# STM32MP13xx register map
File version: 1.5
CPU: CA7 r0p0, little endian, MPU, FPU, 4 interrupt priority bits
Registers are 32-bit, read-write, reset 0x0 unless marked. A register's access mark holds for its fields unless they carry their own. Offsets are from the block's base; [hi:lo] are bit positions; {n}, {i} and the like mark numbered series.

## DDRPHYC (part 1 of 2)
Base 0x5A004000
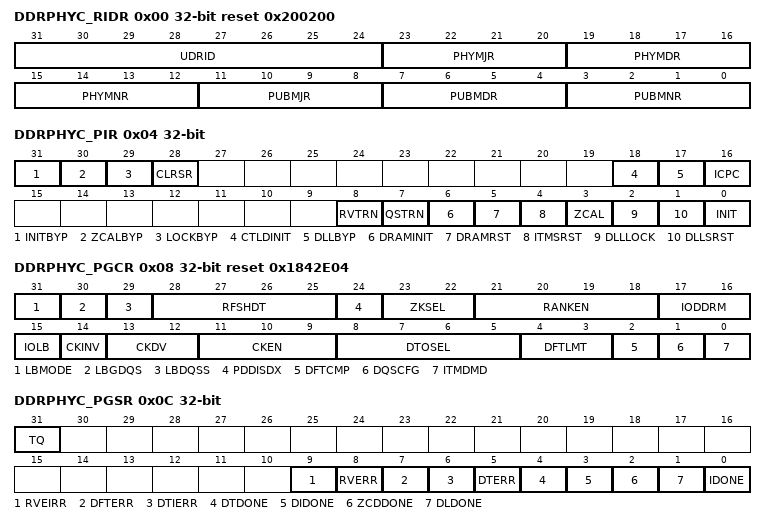
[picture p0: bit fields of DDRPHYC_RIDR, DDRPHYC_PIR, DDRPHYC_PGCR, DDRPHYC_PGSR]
0x00 DDRPHYC_RIDR ro reset 0x200200 — DDRPHYC revision ID register
  [31:24] UDRID — User-defined rev ID
  [23:20] PHYMJR — PHY maj rev
  [19:16] PHYMDR — PHY moderate rev
  [15:12] PHYMNR — PHY minor rev
  [11:8] PUBMJR — PUB maj rev
  [7:4] PUBMDR — PUB moderate rev
  [3:0] PUBMNR — PUB minor rev
0x04 DDRPHYC_PIR wo — DDRPHYC PHY initialization register
  [31] INITBYP — Initialization bypass Bypasses or stops, if set, all initialization routines currently running, including PHY initialization, DRAM initialization, and PHY training. Initialization may be triggered manually using INIT and the other relevant bits of the DDRPHYC_PIR register. This bit is self-clearing.
  [30] ZCALBYP — zcal bypass Bypasses or stops, if set, impedance calibration of all ZQ control blocks that automatically triggers after reset. Impedance calibration may be triggered manually using INIT and ZCAL bits of the DDRPHYC_PIR register. This bit is self-clearing.
  [29] LOCKBYP — DLL lock bypass Bypasses or stops, if set, the waiting of DLLs to lock. DLL lock wait is automatically triggers after reset. DLL lock wait may be triggered manually using INIT and DLLLOCK bits of the DDRPHYC_PIR register. This bit is self-clearing.
  [28] CLRSR — clear status register Writing 1 to this bits does the following: Auto-clears itself. This means a following read to bit CLRSR returns 0 Clears the DXnGSR0 bits for DTDONE, DTERR, DTIERR Clears bit DFTERR in DDRPHYC_PGSR register and bit DFTERR in DDRPHYC_DXnGSR1 register This bit is primarily for debug purposes and is typically not needed during normal functional operation. It can be used when bit IDONE=1 in PGSR register, to manually clear the PGSR status bits, however, the PGSR status bits (except for the DFTRR and TQ bits) are automatically cleared by starting a new init process. The bit can also be used to manually clear the DXnGSR status bits, however, starting a new data training process automatically clears the DXnGSR status bits.
  [18] CTLDINIT — Controller DRAM initialization Indicates if set that DRAM initialization is performed by the controller. Otherwise if not set it indicates that DRAM initialization is performed using the built-in initialization sequence or using software through the configuration port.
  [17] DLLBYP — DLL bypass A setting of 1 on this bit puts all PHY DLLs in bypass mode. A bypassed DLL is also powered down (disabled).
  [16] ICPC — Initialization complete pin configuration Specifies how the DFI 2.1 initialization complete output pin should be used to indicate the status of initialization.
    0=Asserted after PHY initialization (DLL locking and impedance calibration) is complete; 1=Asserted after PHY initialization is complete and the triggered PUBL initialization (DRAM initialization, data training, or initialization trigger with no selected initialization) is complete
  [8] RVTRN — Read DQS gate training DQSTRN) and RV training (RVTRN) should normally be run together. It is expected RVTRN is normally set whenever bit QSTRN is set. If RVTRN=1 and bit QSTRN=0, when bit INIT=1 (triggering the init process) the read DQS gate training algorithm still runs (as if bit QSTRN in DDRPHYC_PIR register was actually set to 1). If it is necessary to run only RV training stand-alone, with no read DQS gate training, you can prevent the read DQS gate training from running by setting bit LBGDQS=1 in DDRPHYC_PGCR register. Note: RV training cannot use multi-purpose register (MPR) and must use the user data programmed in DTDR0-1. Note: RVTRN is not applicable to this version of PUBL.
  [7] QSTRN — Read DQS training Executes a PUBL training routine to determine the optimum position of the read data DQS strobe for maximum system timing margins.
  [6] DRAMINIT — DRAM initialization Executes the DRAM initialization sequence
  [5] DRAMRST — DRAM reset (DDR3 only) Issues a reset to the DRAM (by driving the DRAM reset pin low) and wait 200us. This can be triggered in isolation or with the full DRAM initialization (DRAMINIT). For the latter case, the reset is issued and 200us is waited before starting the full initialization sequence.
  [4] ITMSRST — ITM reset Soft resets the interface timing modules for the data and data strobes, i.e., it asserts the ITM soft reset (srstb) signal.
  [3] ZCAL — Impedance calibration (Driver and ODT) Performs PHY impedance calibration.
  [2] DLLLOCK — DLL lock Waits for the PHY DLLs to lock.
  [1] DLLSRST — DLL soft reset Soft resets all PHY DLLs by driving the DLL soft reset pin. Note: - Requires that ctl_clk be toggling for the DLL soft reset signal to be output from the DLL. If ctl_clk (AC DLL's cclk_0) is not guaranteed to be toggling, it is recommended to use the manual DLL soft reset bit DLLSRST of DDRPHYC_ACDLLCR, and not bit DLLSRST of DDRPHYC_PIR. - Ensure that the minimum requirements for DLL bypass and DLL reset are observed while asserting this bit.
  [0] INIT — Initialization trigger A write of '1' to this bit triggers the DDR system initialization, including PHY initialization, DRAM initialization, and PHY training. The exact initialization steps to be executes are specified in bits 1 to 6 of this register. A bit setting of 1 means the step is executed as part of the initialization sequence, while a setting of '0â means the step is bypassed. The initialization trigger bit is self-clearing.
0x08 DDRPHYC_PGCR reset 0x1842E04 — DDRPHYC PHY global control register
  [31] LBMODE — Loop back mode Indicates if set that the PHY/PUB is in loopback mode
  [30] LBGDQS — Loop back DQS gating Selects the DQS gating mode that should be used when the PHY is in loopback mode. Valid values are:
    0=DQS gate training is triggered on the PUB; 1=DQS gate is set manually using software
  [29] LBDQSS — Loop back DQS shift Selects how the read DQS is shifted during loopback to ensure that the read DQS is centered into the read data eye. Valid values are:
    0=PUB sets the read DQS delay to 0; DQS is already shifted 90 degrees by write path; 1=The read DQS shift is set manually through software
  [28:25] RFSHDT — Refresh during training A non-zero value specifies that a burst of refreshes equal to the number specified in this field should be sent to the SDRAM after training each rank except the last rank.
  [24] PDDISDX — Power down disabled byte Indicates if set that the DLL and I/Os of a disabled byte should be powered down.
  [23:22] ZKSEL — Impedance clock divider selection Selects the divide ratio for the clock used by the impedance control logic. The source clock for the divider is the configuration port clock signal (pclk), depending on which configuration port type used (see âImpedance Calibrationâ on page tbc). Valid values are:
    0=Divide by 2; 1=Divide by 8; 2=Divide by 32; 3=Divide by 64
  [21:18] RANKEN — Rank enable Specifies the ranks that are enabled for data-training. only Bit 0 is used and controls rank 0. Setting the bit to '1â enables the rank, and setting it to '0â disables the rank.
  [17:16] IODDRM — I/O DDR mode Selects the DDR mode for the I/Os.
  [15] IOLB — I/O loop back select Selects where inside the I/O the loop-back of signals happens. Not applicable to D3A I/Os. Valid values are:
    0=Loopback is after output buffer; output enable must be asserted; 1=Loopback is before output buffer; output enable is donât care
  [14] CKINV — CK invert Specifies if set that CK/CK# should be inverted. Otherwise CK/CK# toggles with normal polarity.
  [13:12] CKDV — CK disable value Specifies the static value that should be driven on CK/CK# pair(s) when the pair(s) is disabled. CKDV[0] specifies the value for CK and CKDV[1] specifies the value for CK#.
  [11:9] CKEN — CK enable Controls whether the CK going to the SDRAM is enabled (toggling) or disabled (static value defined by CKDV). One bit for each of the three CK pairs.
  [8:5] DTOSEL — Digital test output select Digital Test Output Select: Selects the PHY digital test output that should be driven onto PHY digital test output (phy_dto) pin: Valid values are: Other: Reserved
    {v}=DATX8 {v} DLL digital test output (v=0..8); 9=AC DLL digital test output
  [4:3] DFTLMT — DQS drift limit Specifies the expected limit of drift on read data strobes. A drift of this value or greater is reported as a drift error through the host port error flag. Valid values are: Note: Although reported through the error flag, this is not an error requiring any action. It is simply an indicator that the drift is greater than expected.
    0=No limit (no error reported); 1=90Â° drift; 2=180Â° drift; 3=270Â° or more drift
  [2] DFTCMP — DQS drift compensation Enables or disables DQS drift compensation. Valid values are: By default, drift compensation is enabled. Note: Drift compensation is not supported under any of the following situations: - LPDDR2/3 (bit DDRMD set to LPDDR2 in DDRPHYC_DCR register) - Burst length 2 (bit BL in DDRPHYC_MR0 register set to burst length of 2) - Read DQS gating using passive windowing (bit DQSCFG in DDRPHYC_PGCR register set to passive windowing) Drift compensation must be set to disabled if any of the above are set.
    0=Disables data strobe drift compensation; 1=Enables data strobe drift compensation
  [1] DQSCFG — DQS gating configuration Selects one of the two DQS gating schemes: Note: Passive windowing must be used for LPDDR2/3.
    0=DQS gating is shut off using the rising edge of DQS_b (active windowing mode); 1=DQS gating blankets the whole burst (passive windowing mode)
  [0] ITMDMD — ITM DDR mode Selects whether ITMS uses DQS and DQS# or it only uses DQS. Valid values are: Note: The correct setting is always DQS and DQS#.
    0=ITMS uses DQS and DQS#; 1=ITMS uses DQS only
0x0C DDRPHYC_PGSR ro — DDRPHYC PHY global status register
  [31] TQ — Temperature output (LPDDR only) N/A
  [9] RVEIRR — Read valid training intermittent error If set, indicates that there was an intermittent error during read valid training, such as a pass was followed by a fail then followed by another pass. Note: RVTRN is not applicable to this version of PUBL
  [8] RVERR — Read valid training error If set, indicates that a valid read valid placement could not be found during read valid training. Note: RVTRN is not applicable to this version of PUBL
  [7] DFTERR — DQS drift error If set, indicates that at least one of the read data strobes has drifted by more than or equal to the drift limit set in the PHY General Configuration Register (PGCR).
  [6] DTIERR — DQS gate training intermittent error If set, indicates that there was an intermittent error during DQS gate training, such as a pass was followed by a fail then followed by another pass.
  [5] DTERR — DQS gate training error If set, indicates that a valid DQS gating window could not be found during DQS gate training.
  [4] DTDONE — Data training done Indicates, if set, that the PHY has finished doing data training.
  [3] DIDONE — DRAM initialization done Indicates if set that DRAM initialization has completed.
  [2] ZCDDONE — zcal done Indicates if set that impedance calibration has completed.
  [1] DLDONE — DLL lock done Indicates if set that DLL locking has completed.
  [0] IDONE — Initialization done Indicates if set that the DDR system initialization has completed. This bit is set after all the selected initialization routines in DDRPHYC_PIR register have completed.
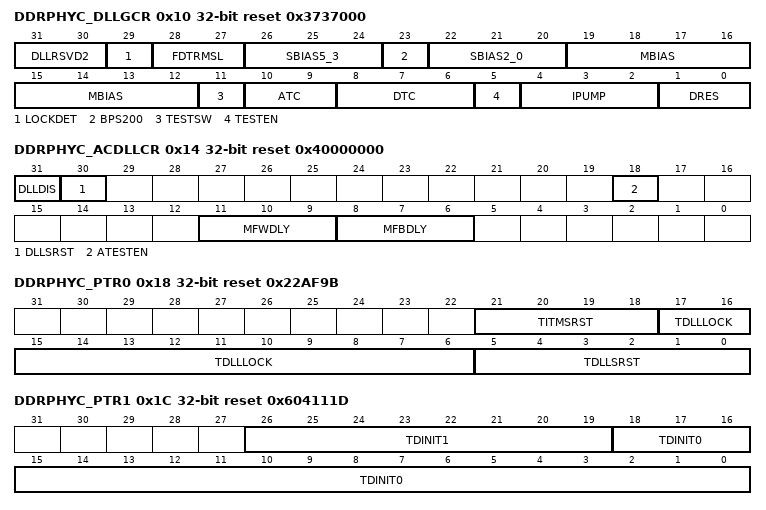
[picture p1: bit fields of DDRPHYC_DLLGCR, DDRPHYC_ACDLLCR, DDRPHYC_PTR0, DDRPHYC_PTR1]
0x10 DDRPHYC_DLLGCR reset 0x3737000 — DDRPHYC DDR DLL global control register
  [31:30] DLLRSVD2 — These bit are connected to the DLL control bus and reserved for future use.
  [29] LOCKDET — Master lock detect enable Note: This field is only valid for a few processes. For all other processes this field is reserved.
  [28:27] FDTRMSL — Slave bypass fixed delay trim
    0=Nominal delay; 1=Nominal delay â 10%; 2=Nominal delay + 10%; 3=Nominal delay + 20%
  [26:24] SBIAS5_3 — Slave bias trim Used to trim the bias for the slave DLL. Note: If DWC_DDR3PHY_DLL_TYPEA Verilog macro is defined then the default value for this field is 0x00.
  [23] BPS200 — Bypass mode frequency range
    0=0 to 100 MHz; 1=0 to 200 MHz
  [22:20] SBIAS2_0 — Slave bias trim Used to trim the bias for the slave DLL. Note: If DWC_DDR3PHY_DLL_TYPEA Verilog macro is defined then the default value for this field is 0x00.
  [19:12] MBIAS — Master bias trim Used to trim the bias for the master DLL. Note: If DWC_DDR3PHY_DLL_TYPEA Verilog macro is defined then the default value for this field is 0x00.
  [11] TESTSW — Test switch Selects the test signals of either the master DLL, set to 0, or the slave DLL, set to 1.
  [10:9] ATC — Analog test control Selects the analog signal to be output on the DLL analog test output (test_out_a) when TESTEN is high (Output is Vss when TESTEN is low). The test output either comes from the master DLL or the slave DLL, depending on the setting of the test switch (TESTSW). Both master DLL and slave DLL output similar analog test signals. Valid settings for analog test control are:
    0=Replica bias output for PMOS (Vbp); 1=Replica bias output for NMOS (Vbn); 2=Filter output (Vc); 3=VDDCORE
  [8:6] DTC — Digital test control Selects the digital signal to be output on the DLL digital test output (test_out_d[1]) when TESTEN is high (Output is '0' when TESTEN is low). Valid settings for master DLL (such as, when TESTSW = '0'): -000: 0 output clock (clk_0) -001: 90 output clock (clk_90) -010: 180 output clock (clk_180) -011: 270 output clock (clk_270) -100: 360 internal clock (clk_360_int) -101: Speed-up pulse (spdup) -110: Slow-down pulse (slwdn) -111: 0 MCTL logic clock (cclk_0) Valid settings for slave DLL (such as when TESTSW = '1'): -000: Input DQS strobe (dqs) -001: Input clock reference (clk_90_in) -010: Internal feedback clock (clk_0_out) -011: 90 output DQS# strobe (dqsb_90) -100: 90 output DQS strobe (dqs_90) -101: Speed-up pulse (spdup) -110: Slow-down pulse (slwdn) -111: Auto-lock enable signal
  [5] TESTEN — Test enable Enables digital and analog test outputs selected by DTC and ATC respectively.
  [4:2] IPUMP — Charge pump current trim Note: If DWC_DDR3PHY_DLL_TYPEA Verilog macro is defined then the default value for this field is 011.
    0=maximum current; 7=minimum current
  [1:0] DRES — Trim reference current versus resistor value variation 1x: Rnom + 20% Note: For a few processes this field is reserved and is not used by the DLL.
    0=Rnom; 1=Rnom - 20%
0x14 DDRPHYC_ACDLLCR reset 0x40000000 — DDRPHYC AC DLL control register
  [31] DLLDIS — DLL disable A disabled DLL is bypassed. By default DLL is enabled.
  [30] DLLSRST — DLL soft reset Soft resets the AC DLL by driving the DLL soft reset pin.
  [18] ATESTEN — Analog test enable Enables the analog test signal to be output on the DLL analog test output (ATO pin). The DLL analog test output is tri-stated when this bit is '0'.
  [11:9] MFWDLY — Master DLL feed-forward delay trim Used to trim the delay in the master DLL feed-forward path:
    0=minimum delay; 7=maximum delay
  [8:6] MFBDLY — Master DLL feed-back delay trim Used to trim the delay in the master DLL feed-back path:
    0=minimum delay; 7=maximum delay
0x18 DDRPHYC_PTR0 reset 0x22AF9B — DDRPHYC PT register 0
  [21:18] TITMSRST — ITM soft reset Number of configuration clock cycles that the ITM soft reset pin must remain asserted when the soft reset is applied to the ITMs. This must correspond to a value that is equal to or more than 8 controller clock cycles. Default value corresponds to 8 controller clock cycles.
  [17:6] TDLLLOCK — DLL lock time Number of configuration clock cycles for the DLL to stabilize and lock, i.e. number of clock cycles from when the DLL reset pin is de-asserted to when the DLL has locked and is ready for use. Default value corresponds to 5.12us at 533MHz.
  [5:0] TDLLSRST — DLL soft reset Number of configuration clock cycles that the DLL soft reset pin must remain asserted when the soft reset is triggered through the PHY initialization register (DDRPHYC_PIR). This must correspond to a value that is equal to or more than 50ns or 8 controller clock cycles, whichever is bigger. Default value corresponds to 50Â ns at 533Â MHz.
0x1C DDRPHYC_PTR1 reset 0x604111D — DDRPHYC PT register 1
  [26:19] TDINIT1 — tDINIT1 DRAM initialization time corresponding to the following: DDR3 = CKE high time to first command (tRFC +10 ns or 5 tCK, whichever value is larger) LPDDR2 = CKE low time with power and clock stable (100 ns) LPDDR3 = CKE low time with power and clock stable (100 ns) Default value corresponds to DDR3 360ns at 533MHz.
  [18:0] TDINIT0 — tDINIT0 DRAM initialization time corresponding to the following: DDR3 = CKE low time with power and clock stable (500 us) LPDDR2 = CKE high time to first command (200 us) LPDDR3 = CKE high time to first command (200us) Default value corresponds to DDR3 500 us at 533MHz.
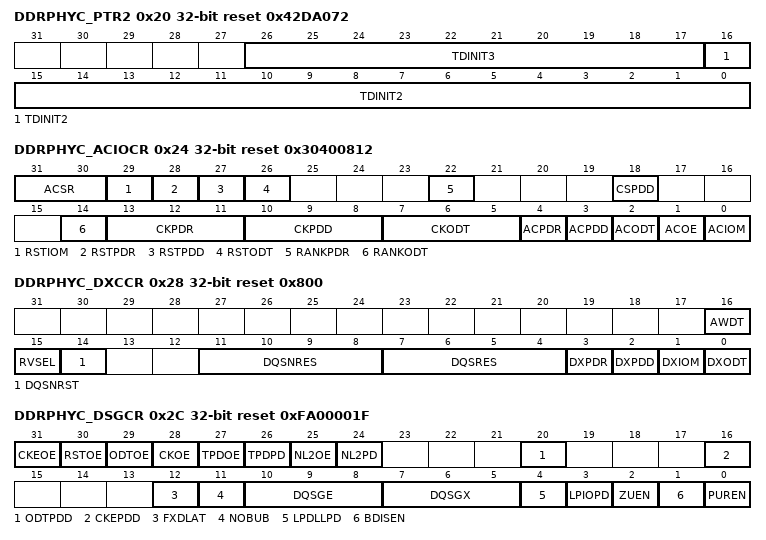
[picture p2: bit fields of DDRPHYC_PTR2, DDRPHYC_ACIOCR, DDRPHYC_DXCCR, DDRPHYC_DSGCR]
0x20 DDRPHYC_PTR2 reset 0x42DA072 — DDRPHYC PT register 2
  [26:17] TDINIT3 — tDINIT3 DRAM initialization time corresponding to the following: LPDDR2 = Time from ZQ initialization command to first command (1 us) LPDDR3 = Time from ZQ initialization command to first command (1us) Default value corresponds to the LPDDR2/3 1 us at 533MHz.
  [16:0] TDINIT2 — tDINIT2 DRAM initialization time corresponding to the following: DDR3 = Reset low time (200 us on power-up or 100 ns after power-up) LPDDR2 = Time from reset command to end of auto initialization (1 us + 10 us = 11us) LPDDR3 = Time from reset command to end of auto initialization (11us) Default value corresponds to DDR3 200 us at 533MHz
0x24 DDRPHYC_ACIOCR reset 0x30400812 — DDRPHYC ACIOC register
  [31:30] ACSR — AC slew rate Selects slew rate of the I/O for all address and command pins.
  [29] RSTIOM — Reset I/O mode Selects SSTL mode (when set to 0) or CMOS mode (when set to 1) of the I/O for SDRAM Reset.
  [28] RSTPDR — RST pin power down receiver Powers down, when set, the input receiver on the I/O for SDRAM RST# pin.
  [27] RSTPDD — RST pin power down driver Powers down, when set, the output driver on the I/O for SDRAM RST# pin.
  [26] RSTODT — RST pin ODT Enables, when set, the on-die termination on the I/O for SDRAM RST# pin.
  [22] RANKPDR — Rank power down receiver Powers down, when set, the input receiver on the I/O CKE, ODT, and CS# pins. Only RANKPDR[0] is used for single rank
  [18] CSPDD — CS power down driver Powers down, when set, the output driver on the I/O for CS# pins. Only PDD[0] is used for single rank. CKE and ODT driver power down is controlled by DSGCR register.
  [14] RANKODT — Rank ODT Enables, when set, the on-die termination on the I/O for CKE, ODT, and CS# pins.
  [13:11] CKPDR — CK pin power down receiver Powers down, when set, the input receiver on the I/O for CK[0], CK[1], and CK[2] pins, respectively
  [10:8] CKPDD — CK pin power down driver Powers down, when set, the output driver on the I/O for CK[0], CK[1], and CK[2] pins, respectively.
  [7:5] CKODT — CK pin ODT Enables, when set, the on-die termination on the I/O for CK[0], CK[1], and CK[2] pins, respectively.
  [4] ACPDR — AC pins power down receivers Powers down, when set, the input receiver on the I/O for RAS#, CAS#, WE#, BA[2:0], and A[15:0] pins.
  [3] ACPDD — AC pins power down drivers Powers down, when set, the output driver on the I/O for RAS#, CAS#, WE#, BA[2:0], and A[15:0] pins
  [2] ACODT — AC pins ODT Enables, when set, the on-die termination on the I/O for RAS#, CAS#, WE#, BA[2:0], and A[15:0] pins
  [1] ACOE — AC pins output enable Enables, when set, the output driver on the I/O for all address and command pins
  [0] ACIOM — AC pins I/O mode Selects SSTL mode (when set to 0) or CMOS mode (when set to 1) of the I/O for all address and command pins,
0x28 DDRPHYC_DXCCR reset 0x800 — DDRPHYC DXCC register
  [16] AWDT — Active window data train Indicates if set that data training (DQS gate training and read valid training) should be performed with active DQS gate window. This is just for debug purposes. The default is to perform training with passive windowing.
  [15] RVSEL — ITMD read valid select Selects the scheme used for ITMD read valid. Valid values are:
    0=ITMD read valid signal is generated by delayed DFI read enable signal; 1=ITMD read valid is generated by the ITMD itself using asynchronous crossing
  [14] DQSNRST — DQS reset Indicates, if set, that the ITMS of DQS# should always be put in reset such that its output enable is always '1' and its data output is always '0'. This is done by driving the oe_set_b and do_rst_b pins of this ITMS to '0' in order to force the unused DQS# PAD to a known state of '0' in applications that don't use DQS#.
  [11:8] DQSNRES — DQS# resistor Selects the on-die pull-up/pull-down resistor for DQS# pins. Same encoding as DQSRES. Note: DQS# resistor must be connected for LPDDR2.
  [7:4] DQSRES — DQS resistor Selects the on-die pull-down/pull-up resistor for DQS pins. DQSRES[3] selects pull-down (when set to 0) or pull-up (when set to 1). DQSRES[2:0] selects the resistor value as follows: Note: DQS resistor must be connected for LPDDR2
    0=Open: On-die resistor disconnected; 1=688 Î©; 2=611 Î©; 3=550 Î©; 4=500 Î©; 5=458 Î©; 6=393 Î©; 7=344 Î©
  [3] DXPDR — Data power down receiver Powers down, when set, the input receiver on I/O for DQ, DM, and DQS/DQS# pins of all DATX8 macros. It also powers down the PDQSR cell of all DAXT8 macros. This bit is ORed with the PDR and DQSRPD configuration bits of the individual DATX8
  [2] DXPDD — Data power down driver Powers down, when set, the output driver on I/O for DQ, DM, and DQS/DQS# pins of all DATX8 macros. This bit is ORed with the PDD configuration bit of the individual DATX8.
  [1] DXIOM — Data I/O mode Selects SSTL mode (when set to 0) or CMOS mode (when set to 1) of the I/O for DQ, DM, and DQS/DQS# pins of all DATX8 macros. This bit is ORed with the IOM configuration bit of the individual DATX8.
  [0] DXODT — Data on die termination Enables, when set, the on-die termination on the I/O for DQ, DM, and DQS/DQS# pins of all DATX8 macros. This bit is ORed with the ODT configuration bit of the individual DATX8.
0x2C DDRPHYC_DSGCR reset 0xFA00001F — DDRPHYC DSGC register
  [31] CKEOE — CKE output enable Sets the output driver on the I/O for SDRAM CKE pins.
  [30] RSTOE — RST output enable Enables, when set, the output driver on the I/O for SDRAM RST# pin
  [29] ODTOE — ODT output enable Enables, when set, the output driver on the I/O for SDRAM ODT pins.
  [28] CKOE — CK output enable Enables, when set, the output driver on the I/O for SDRAM CK/CK# pins.
  [27] TPDOE — TPD output enable (N/A LPDDR only)
  [26] TPDPD — TPD power down driver (N/A LPDDR only)
  [25] NL2OE — Non LPDDR2 output enable Enables, when set, the output driver on the I/O for non-LPDDR2/LPDDR3 (ODT, RAS#, CAS#, WE#, and BA) pins. This may be used when a chip that is designed for both LPDDR2/LPDDR3 and other DDR modes is being used in LPDDR2/LPDDR3 mode. For these pins, the I/O output enable signal (OE) is an AND of this bit and the respective output enable bit in ACIOCR or DSGCR registers.
  [24] NL2PD — Non LPDDR2 power down Powers down, when set, the output driver and the input receiver on the I/O for non-LPDDR2/LPDDR3 (ODT, RAS#, CAS#, WE#, and BA) pins. This may be used when a chip that is designed for both LPDDR2/LPDDR3 and other DDR modes is being used in LPDDR2/LPDDR3 mode. For these pins, the I/O power down signal (PDD or PDR) is an OR of this bit and the respective power-down bit in ACIOCR register.
  [20] ODTPDD — ODT power down driver Powers down, when set, the output driver on the I/O for ODT pin.
  [16] CKEPDD — CKE power down driver Powers down, when set, the output driver on the I/O for CKE pin.
  [12] FXDLAT — Fixed latency Specified whether all reads should be returned to the controller with a fixed read latency. Enabling fixed read latency increases the read latency. Valid values are:
    0=Disable fixed read latency; 1=Enable fixed read latency
  [11] NOBUB — No bubble Specified whether reads should be returned to the controller with no bubbles. Enabling no-bubble reads increases the read latency. Valid values are:
    0=Bubbles are allowed during reads; 1=Bubbles are not allowed during reads
  [10:8] DQSGE — DQS gate early Specifies the number of clock cycles for which the DQS gating must be enable dearlier than its normal position. Only applicable when using PDQSR I/O cell, passive DQS gating and no drift compensation. This field is recommended to be set to zero for all DDR types other than LPDDR2/LPDDR3. For LPDDR2/LPDDR3 it should be set to (tDQSCKmax - tDQSCKmin) divide by clock period and rounded up. tDQSCKmax and tDQSCKmin can be found in the LPDDR/LPDDR2 vendor datasheet.
  [7:5] DQSGX — DQS gate extension Specifies the number of clock cycles for which the DQS gating must be extended beyond the normal burst length width. Only applicable when using PDQSR I/O cell, passive DQS gating and no drift compensation. This field is recommended to be set to zero for all DDR types other than LPDDR2/LPDDR3. For LPDDR2/LPDDR3 it should be set to (tDQSCKmax- tDQSCKmin) divide by clock period and rounded up. tDQSCKmax and tDQSCKmin can be found in the LPDDR2 vendor datasheet.
  [4] LPDLLPD — Low power DLL power down Specifies if set that the PHY should respond to the DFI low power opportunity request and power down the DLL of the PHY if the wakeup time request satisfies the DLL lock time. For more information on requirements when enabling and disabling the DLL, refer to âbypass mode register controlâ
  [3] LPIOPD — Low power I/O power down Specifies if set that the PHY should respond to the DFI low power opportunity request and power down the I/Os of the PHY.
  [2] ZUEN — zcal on DFI update request Specifies if set that the PHY should perform impedance calibration (update) whenever there is a controller initiated DFI update request. Otherwise the PHY ignores an update request from the controller.
  [1] BDISEN — Byte disable enable Specifies if set that the PHY should respond to DFI byte disable request. Otherwise the byte disable from the DFI is ignored in which case bytes can only be disabled using the DXnGCR register
  [0] PUREN — PHY update request enable Specifies if set, that the PHY should issue PHY initiated DFI update request when there is DQS drift of more than Â¾ of a clock cycle within one continuous (back-to-back) read burst. By default the PHY issues PHY initiated update requests and the controller should respond otherwise the PHY may return erroneous values. The option to disable it is provided only for silicon evaluation and testing.
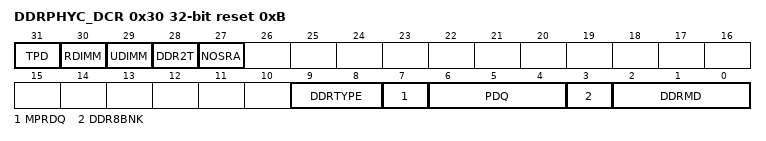
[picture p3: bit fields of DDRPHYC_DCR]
0x30 DDRPHYC_DCR reset 0xB — DDRPHYC DC register
  [31] TPD — Test power down (N/A LPDDR only) If set it places the DRAM in deep power down mode.
  [30] RDIMM — Registered DIMM Indicates if set that a registered DIMM is used. In this case, the PUBL increases the SDRAM write and read latencies (WL/RL) by 1. This only applies to PUBL internal SDRAM transactions. Transactions generated by the controller must make its own adjustments to WL/RL when using a registered DIMM
  [29] UDIMM — Unbuffered DIMM Indicates if set that there is address mirroring on the second rank of an un-buffered DIMM (the rank connected to CS#[1]). In this case, the PUBL re-scrambles the bank and address when sending mode register commands to the second rank. This only applies to PUBL internal SDRAM transactions. Transactions generated by the controller must make its own adjustments when using an un-buffered DIMM. DCR[NOSRA] must be set if address mirroring is enabled.
  [28] DDR2T — 2T timing Indicates if set that 2T timing should be used by PUB internally generated SDRAM transactions.
  [27] NOSRA — No simultaneous rank access Specifies if set that simultaneous rank access on the same clock cycle is not allowed. This means that multiple chip select signals should not be asserted at the same time. This may be required on some DIMM systems.
  [9:8] DDRTYPE — DDR type (LPDDR2 S4) Selects the DDR type for the specified LPDDR mode. Valid values for LPDDR2 are: Others: Reserved
    0=LPDDR2-S4; 1=LPDDR2-S2
  [7] MPRDQ — MPR DQ Specifies the value that is driven on non-primary DQ pins during MPR reads. Valid values are:
    0=Primary DQ drives out the data from MPR (0-1-0-1); non-primary DQs drive '0â; 1=Primary DQ and non-primary DQs all drive the same data from MPR (0-1-0-1)
  [6:4] PDQ — Primary DQ(DDR3 Only) Specifies the DQ pin in a byte that is designated as a primary pin for Multi-Purpose Register (MPR) reads. Valid values are 0 to 7 for DQ[0] to DQ[7], respectively
  [3] DDR8BNK — DDR 8 banks Indicates if set that the SDRAM used has 8 banks. tRPA = tRP+1 and tFAW are used for 8-bank DRAMs, other tRPA = tRP and no tFAW is used. Note: A setting of 1 for DRAMs that have fewer than 8 banks still results in correct functionality but less tighter DRAM command spacing for the parameters described here.
  [2:0] DDRMD — SDRAM DDR mode Others: Reserved
    3=DDR3; 4=LPDDR2 (Mobile DDR2); 5=LPDDR3 (Mobile DDR3)
